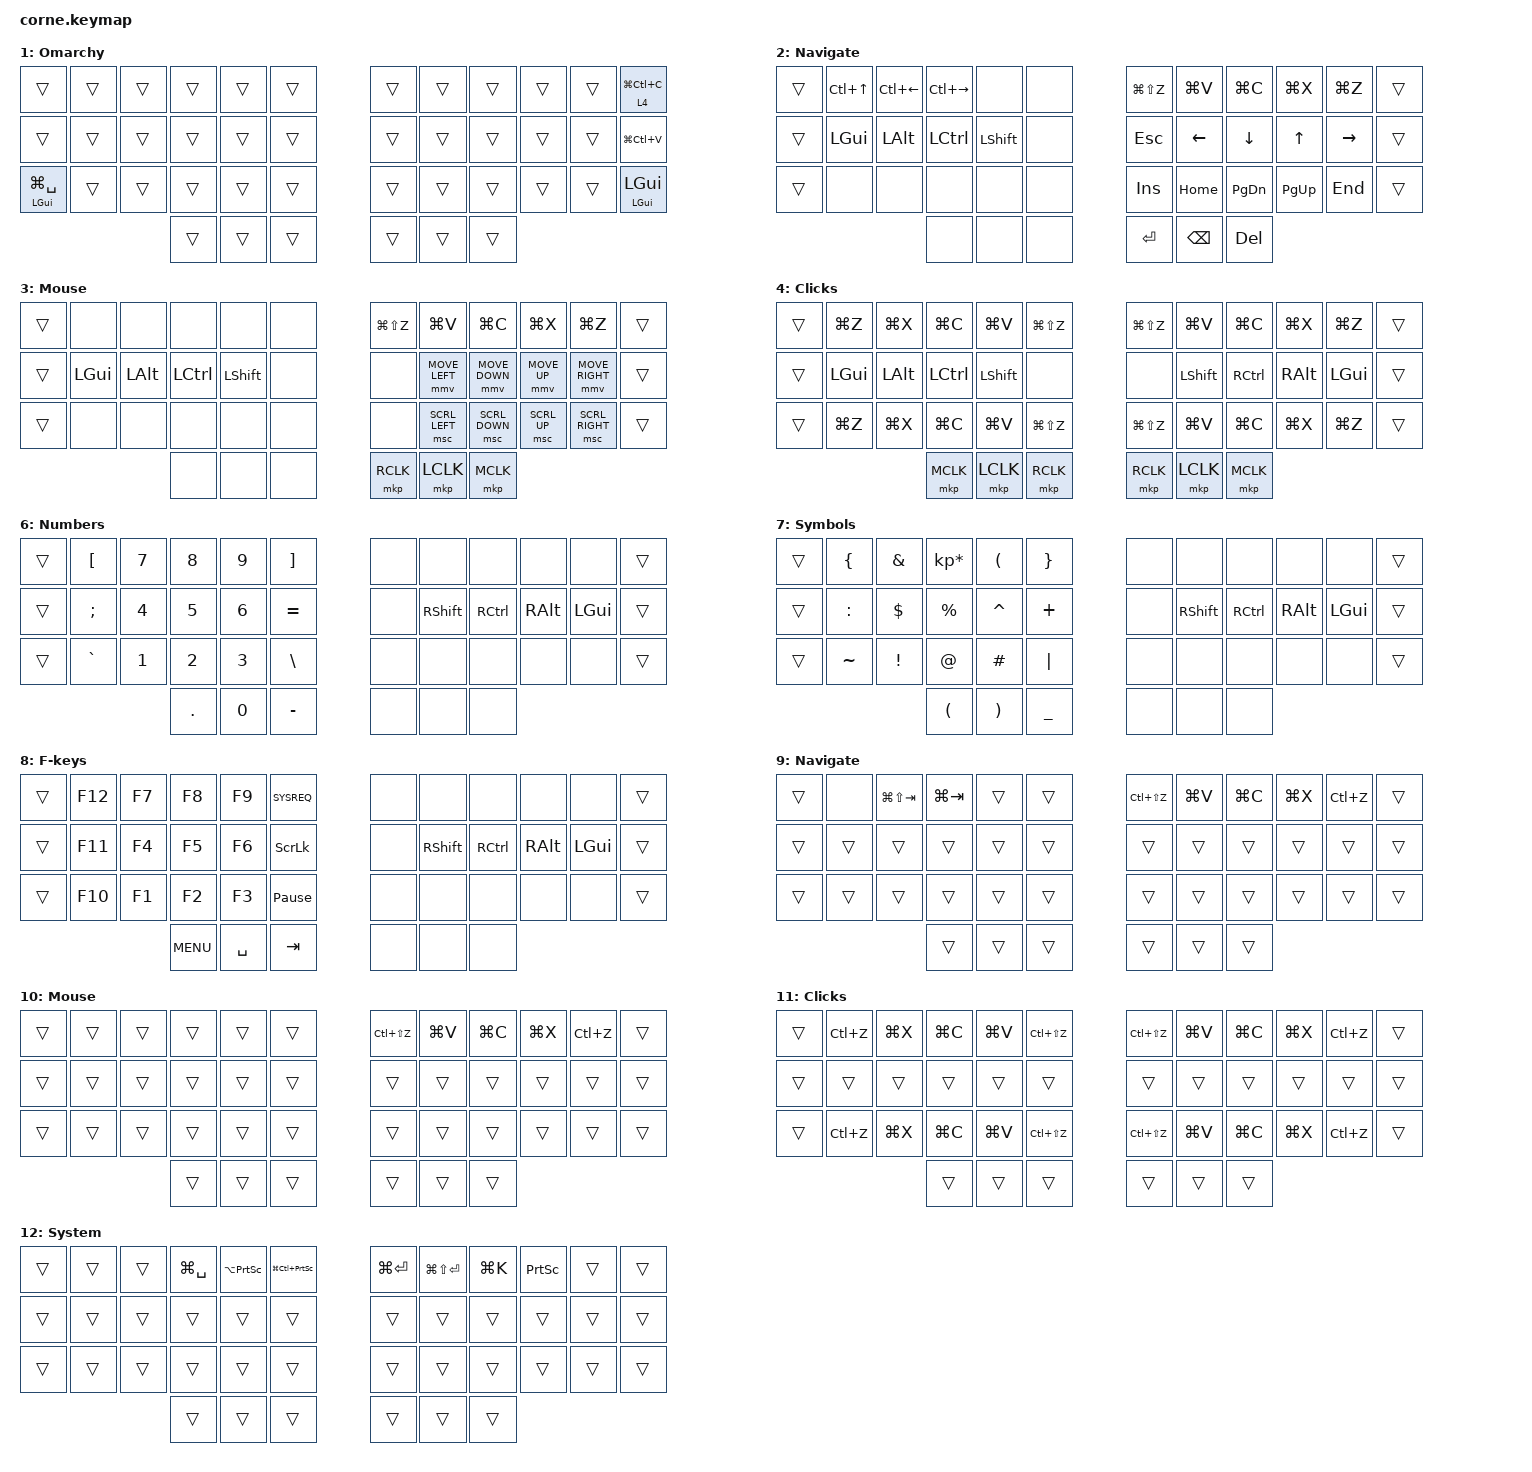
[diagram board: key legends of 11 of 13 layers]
/*
 * Copyright (c) 2020 The ZMK Contributors
 *
 * SPDX-License-Identifier: MIT
 */

#include <behaviors.dtsi>
#include <dt-bindings/zmk/bt.h>
#include <dt-bindings/zmk/ext_power.h>
#include <dt-bindings/zmk/keys.h>
#include <dt-bindings/zmk/outputs.h>
#include <dt-bindings/zmk/pointing.h>
#include <input/processors.dtsi>

/* Mouse feel. ZMK's curve is: speed(t) = max * (t / time-to-max-speed-ms) ^ exponent,
 * capped at max once t passes the ramp. Stock is max 600, ramp 300ms, exponent 1.
 *
 * Doubling the ramp (300 -> 600) and doubling the scaler cancel out for the first
 * 300ms, so taps shorter than that move EXACTLY as far as stock. What changes is
 * that a hold no longer plateaus at 300ms - it keeps accelerating to 2x the old
 * top speed. Precision unchanged, ceiling raised.
 *
 * To actually slow the start: raise the ramp past 2x the scaler (e.g. 900 with
 * scaler 2 1), or set acceleration-exponent = <2> for a much flatter opening.
 * zip_xy_scaler M D multiplies every movement by M/D; both args must stay <= 16.
 * Delete this block to go back to stock - nothing is persisted on the board. */
&mmv {
    time-to-max-speed-ms = <600>;
    acceleration-exponent = <1>;
};

&mmv_input_listener {
    input-processors = <&zip_xy_scaler 2 1>;
};

/ {
    behaviors {
        sticky_hyper: sticky_hyper {
            compatible = "zmk,behavior-sticky-key";
            #binding-cells = <1>;
            bindings = <&kp>;
            release-after-ms = <1500>;
            quick-release;
            lazy;
            ignore-modifiers;
        };

        hyper: hyper_hold_sticky {
            compatible = "zmk,behavior-hold-tap";
            #binding-cells = <2>;
            bindings = <&kp>, <&sticky_hyper>;
            flavor = "hold-preferred";
            tapping-term-ms = <180>;
            quick-tap-ms = <0>;
        };

        launcher: launcher_hyper {
            compatible = "zmk,behavior-hold-tap";
            #binding-cells = <2>;
            bindings = <&kp>, <&kp>;
            flavor = "hold-preferred";
            tapping-term-ms = <180>;
            quick-tap-ms = <0>;
        };

        hml: home_row_mods_left {
            compatible = "zmk,behavior-hold-tap";
            label = "HOMEROW_MODS_LEFT_HAND";
            bindings = <&kp>, <&kp>;

            #binding-cells = <2>;
            tapping-term-ms = <280>;
            hold-trigger-key-positions = <6 7 8 9 10 11 18 19 20 21 22 23 30 31 32 33 34 35 39 40 41>;
            flavor = "balanced";
            hold-trigger-on-release;
            hold-while-undecided;
            quick-tap-ms = <175>;
            require-prior-idle-ms = <150>;
        };

        hmr: home_row_mods_right {
            compatible = "zmk,behavior-hold-tap";
            label = "HOMEROW_MODS_RIGHT_HAND";
            bindings = <&kp>, <&kp>;

            #binding-cells = <2>;
            tapping-term-ms = <280>;
            hold-trigger-key-positions = <0 1 2 3 4 5 12 13 14 15 16 17 24 25 26 27 28 29 36 37 38>;
            flavor = "balanced";
            hold-while-undecided;
            hold-trigger-on-release;
            quick-tap-ms = <175>;
            require-prior-idle-ms = <150>;
        };
    };

    // Host mode selects the corresponding overlay when a shared layer is held.
    // Explicit Linux clipboard bindings preserve priority when layers are chorded.
    conditional_layers {
        compatible = "zmk,conditional-layers";
        omarchy_navigate { if-layers = <1 2>; then-layer = <9>; };
        omarchy_mouse { if-layers = <1 3>; then-layer = <10>; };
        omarchy_clicks { if-layers = <1 4>; then-layer = <11>; };
        omarchy_system { if-layers = <1 5>; then-layer = <12>; };
    };

    keymap {
        compatible = "zmk,keymap";

        mac_layer {
            // Right top: capture/Clicks. Right bottom: one-shot Hyper / held Hyper.
            bindings = <
&kp LG(GRAVE)                         &kp Q        &kp W        &kp F         &kp P         &kp B    &kp J  &kp L         &kp U         &kp Y        &kp APOS     &lt 4 LG(LS(N5))
&caps_word                            &hml LGUI A  &hml LALT R  &hml LCTRL S  &hml LSHFT T  &kp G    &kp M  &hmr RSHFT N  &hmr RCTRL E  &hmr LALT I  &hmr LGUI O  &kp LS(LA(LC(LG(V))))
&launcher LS(LA(LC(LGUI))) LG(SPACE)  &kp Z        &kp X        &kp C         &kp D         &kp V    &kp K  &kp H         &kp COMMA     &kp DOT      &kp SLASH    &hyper LS(LA(LC(LGUI))) LS(LA(LC(LGUI)))
                                                              &lt 5 ESC   &lt 2 SPACE  &lt 3 TAB     &lt 7 ENTER  &lt 6 BACKSPACE  &lt 8 DELETE
            >;

            label = "Mac";
            display-name = "Mac";
        };

        omarchy_layer {
            // Same positions: scratchpad/capture, Caps Word/clipboard, menu/Super.
            bindings = <
&trans                    &trans  &trans  &trans  &trans  &trans    &trans  &trans  &trans  &trans  &trans  &lt 4 LG(LC(C))
&trans                    &trans  &trans  &trans  &trans  &trans    &trans  &trans  &trans  &trans  &trans  &kp LG(LC(V))
&launcher LGUI LG(SPACE)  &trans  &trans  &trans  &trans  &trans    &trans  &trans  &trans  &trans  &trans  &hyper LGUI LGUI
                              &trans      &trans      &trans        &trans      &trans      &trans
            >;

            label = "Omarchy";
            display-name = "Omarchy";
        };

        navigate_layer {
            bindings = <
&trans  &kp LC(UP)  &kp LC(LEFT)  &kp LC(RIGHT)  &none      &none    &kp LG(LS(Z))  &kp LG(V)  &kp LG(C)      &kp LG(X)    &kp LG(Z)  &trans
&trans  &kp LGUI    &kp LALT      &kp LCTRL      &kp LSHFT  &none    &kp ESC        &kp LEFT   &kp DOWN       &kp UP       &kp RIGHT  &trans
&trans  &none       &none         &none          &none      &none    &kp INSERT     &kp HOME   &kp PAGE_DOWN  &kp PAGE_UP  &kp END    &trans
                               &none       &none       &none         &kp ENTER   &kp BACKSPACE  &kp DELETE
            >;

            label = "Navigate";
            display-name = "Navigate";
        };

        mouse_layer {
            bindings = <
&trans  &none     &none     &none      &none      &none    &kp LG(LS(Z))  &kp LG(V)       &kp LG(C)       &kp LG(X)     &kp LG(Z)        &trans
&trans  &kp LGUI  &kp LALT  &kp LCTRL  &kp LSHFT  &none    &none          &mmv MOVE_LEFT  &mmv MOVE_DOWN  &mmv MOVE_UP  &mmv MOVE_RIGHT  &trans
&trans  &none     &none     &none      &none      &none    &none          &msc SCRL_LEFT  &msc SCRL_DOWN  &msc SCRL_UP  &msc SCRL_RIGHT  &trans
                     &none       &none       &none         &mkp RCLK   &mkp LCLK   &mkp MCLK
            >;

            label = "Mouse";
            display-name = "Mouse";
        };

        clicks_layer {
            bindings = <
&trans  &kp LG(Z)  &kp LG(X)  &kp LG(C)  &kp LG(V)  &kp LG(LS(Z))    &kp LG(LS(Z))  &kp LG(V)  &kp LG(C)  &kp LG(X)  &kp LG(Z)  &trans
&trans  &kp LGUI   &kp LALT   &kp LCTRL  &kp LSHFT  &none            &none          &kp LSHFT  &kp RCTRL  &kp RALT   &kp LGUI   &trans
&trans  &kp LG(Z)  &kp LG(X)  &kp LG(C)  &kp LG(V)  &kp LG(LS(Z))    &kp LG(LS(Z))  &kp LG(V)  &kp LG(C)  &kp LG(X)  &kp LG(Z)  &trans
                               &mkp MCLK   &mkp LCLK   &mkp RCLK     &mkp RCLK   &mkp LCLK   &mkp MCLK
            >;

            label = "Clicks";
            display-name = "Clicks";
        };

        system_layer {
            // Hold Escape, then Q for Mac or W for Omarchy.
            bindings = <
&trans  &to 0     &to 1     &kp LS(LA(LC(LG(O))))  &kp LG(LS(N3))  &kp LG(LS(N5))    &kp LS(LA(LC(LG(T))))  &kp LS(LA(LC(LG(B))))  &kp LS(LA(LC(LG(K))))  &kp LG(LS(N4))   &none       &trans
&trans  &kp LGUI  &kp LALT  &kp LCTRL              &kp LSHFT       &none             &ext_power EP_TOG      &kp C_PREVIOUS         &kp C_VOLUME_DOWN      &kp C_VOLUME_UP  &kp C_NEXT  &trans
&trans  &none     &none     &none                  &none           &none             &out OUT_TOG           &bt BT_SEL 0           &bt BT_SEL 1           &bt BT_SEL 2     &bt BT_CLR  &trans
                                               &none       &none       &none         &kp C_PLAY_PAUSE  &kp C_NEXT  &kp K_MUTE
            >;

            label = "System";
            display-name = "System";
        };

        numbers_layer {
            bindings = <
&trans  &kp LBKT   &kp N7  &kp N8  &kp N9  &kp RIGHT_BRACKET    &none  &none      &none      &none     &none     &trans
&trans  &kp SEMI   &kp N4  &kp N5  &kp N6  &kp EQUAL            &none  &kp RSHFT  &kp RCTRL  &kp RALT  &kp LGUI  &trans
&trans  &kp GRAVE  &kp N1  &kp N2  &kp N3  &kp BACKSLASH        &none  &none      &none      &none     &none     &trans
                          &kp DOT     &kp N0      &kp MINUS     &none       &none       &none
            >;

            label = "Numbers";
            display-name = "Numbers";
        };

        symbols_layer {
            bindings = <
&trans  &kp LEFT_BRACE  &kp AMPERSAND    &kp KP_MULTIPLY  &kp LEFT_PARENTHESIS  &kp RIGHT_BRACE    &none  &none      &none      &none     &none     &trans
&trans  &kp COLON       &kp DOLLAR       &kp PERCENT      &kp CARET             &kp PLUS           &none  &kp RSHFT  &kp RCTRL  &kp RALT  &kp LGUI  &trans
&trans  &kp TILDE       &kp EXCLAMATION  &kp AT_SIGN      &kp HASH              &kp PIPE           &none  &none      &none      &none     &none     &trans
                                    &kp LEFT_PARENTHESIS  &kp RIGHT_PARENTHESIS  &kp UNDERSCORE    &none       &none       &none
            >;

            label = "Symbols";
            display-name = "Symbols";
        };

        fkeys_layer {
            bindings = <
&trans  &kp F12  &kp F7  &kp F8  &kp F9  &kp SYSREQ         &none  &none      &none      &none     &none     &trans
&trans  &kp F11  &kp F4  &kp F5  &kp F6  &kp SCROLLLOCK     &none  &kp RSHFT  &kp RCTRL  &kp RALT  &kp LGUI  &trans
&trans  &kp F10  &kp F1  &kp F2  &kp F3  &kp PAUSE_BREAK    &none  &none      &none      &none     &none     &trans
                      &kp C_MENU  &kp SPACE   &kp TAB       &none       &none       &none
            >;

            label = "F-keys";
            display-name = "F-keys";
        };

        omarchy_navigate_layer {
            bindings = <
&trans  &none   &kp LG(LS(TAB))  &kp LG(TAB)  &trans  &trans    &kp LC(LS(Z))  &kp LG(V)  &kp LG(C)  &kp LG(X)  &kp LC(Z)  &trans
&trans  &trans  &trans           &trans       &trans  &trans    &trans         &trans     &trans     &trans     &trans     &trans
&trans  &trans  &trans           &trans       &trans  &trans    &trans         &trans     &trans     &trans     &trans     &trans
                          &trans      &trans      &trans        &trans      &trans      &trans
            >;

            label = "Omarchy Navigate";
            display-name = "Navigate";
        };

        omarchy_mouse_layer {
            bindings = <
&trans  &trans  &trans  &trans  &trans  &trans    &kp LC(LS(Z))  &kp LG(V)  &kp LG(C)  &kp LG(X)  &kp LC(Z)  &trans
&trans  &trans  &trans  &trans  &trans  &trans    &trans         &trans     &trans     &trans     &trans     &trans
&trans  &trans  &trans  &trans  &trans  &trans    &trans         &trans     &trans     &trans     &trans     &trans
            &trans      &trans      &trans        &trans      &trans      &trans
            >;

            label = "Omarchy Mouse";
            display-name = "Mouse";
        };

        omarchy_clicks_layer {
            bindings = <
&trans  &kp LC(Z)  &kp LG(X)  &kp LG(C)  &kp LG(V)  &kp LC(LS(Z))    &kp LC(LS(Z))  &kp LG(V)  &kp LG(C)  &kp LG(X)  &kp LC(Z)  &trans
&trans  &trans     &trans     &trans     &trans     &trans           &trans         &trans     &trans     &trans     &trans     &trans
&trans  &kp LC(Z)  &kp LG(X)  &kp LG(C)  &kp LG(V)  &kp LC(LS(Z))    &kp LC(LS(Z))  &kp LG(V)  &kp LG(C)  &kp LG(X)  &kp LC(Z)  &trans
                               &trans      &trans      &trans        &trans      &trans      &trans
            >;

            label = "Omarchy Clicks";
            display-name = "Clicks";
        };

        omarchy_system_layer {
            bindings = <
&trans  &trans  &trans  &kp LG(SPACE)  &kp LA(PSCRN)  &kp LG(LC(PSCRN))    &kp LG(ENTER)  &kp LG(LS(ENTER))  &kp LG(K)  &kp PSCRN  &trans  &trans
&trans  &trans  &trans  &trans         &trans         &trans               &trans         &trans             &trans     &trans     &trans  &trans
&trans  &trans  &trans  &trans         &trans         &trans               &trans         &trans             &trans     &trans     &trans  &trans
                                     &trans      &trans      &trans        &trans      &trans      &trans
            >;

            label = "Omarchy System";
            display-name = "System";
        };
    };
};
